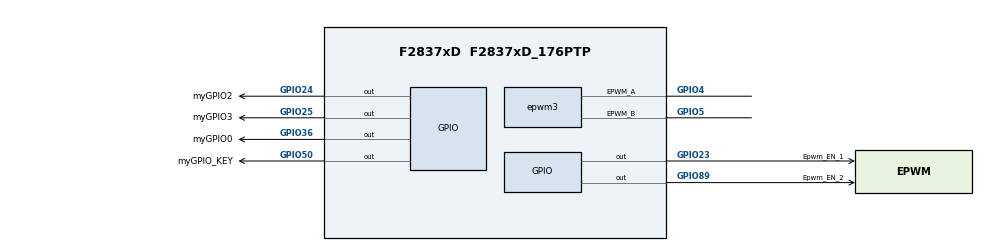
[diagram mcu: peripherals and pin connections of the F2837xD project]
/**
 *
 * @cliArgs --device "F2837xD" --part "F2837xD_176PTP" --package "F2837xD_176PTP" --context "CPU1" --product "C2000WARE@26.01.00.00"
 * @versions {"tool":"1.28.0+4696"}
 */

/**
 * Import the modules used in this configuration.
 */
const adc            = scripting.addModule("/driverlib/adc.js", {}, false);
const adc1           = adc.addInstance();
const adc2           = adc.addInstance();
const adc3           = adc.addInstance();
const cmpss          = scripting.addModule("/driverlib/cmpss.js", {}, false);
const cmpss1         = cmpss.addInstance();
const cmpss2         = cmpss.addInstance();
const cmpss3         = cmpss.addInstance();
const device_support = scripting.addModule("/driverlib/device_support.js");
const epwm           = scripting.addModule("/driverlib/epwm.js", {}, false);
const epwm1          = epwm.addInstance();
const epwm2          = epwm.addInstance();
const epwm3          = epwm.addInstance();
const epwm4          = epwm.addInstance();
const epwm5          = epwm.addInstance();
const epwm6          = epwm.addInstance();
const epwm7          = epwm.addInstance();
const epwm8          = epwm.addInstance();
const epwm9          = epwm.addInstance();
const epwmxbar       = scripting.addModule("/driverlib/epwmxbar.js", {}, false);
const epwmxbar1      = epwmxbar.addInstance();
const gpio           = scripting.addModule("/driverlib/gpio.js", {}, false);
const gpio1          = gpio.addInstance();
const gpio2          = gpio.addInstance();
const gpio3          = gpio.addInstance();
const gpio4          = gpio.addInstance();
const gpio5          = gpio.addInstance();
const gpio6          = gpio.addInstance();
const sysctl         = scripting.addModule("/driverlib/sysctl.js");
const FPUfastRTS     = scripting.addModule("/libraries/math/FPUfastRTS/FPUfastRTS.js", {}, false);
const FPUfastRTS1    = FPUfastRTS.addInstance();

/**
 * Write custom configuration values to the imported modules.
 */
adc1.$name               = "myADC0";
adc1.adcClockPrescaler   = "ADC_CLK_DIV_4_0";
adc1.enabledSOCs         = ["ADC_SOC_NUMBER2","ADC_SOC_NUMBER3","ADC_SOC_NUMBER4","ADC_SOC_NUMBER5"];
adc1.soc2Channel         = "ADC_CH_ADCIN2";
adc1.soc2SampleWindow    = 15;
adc1.soc3Channel         = "ADC_CH_ADCIN3";
adc1.soc3SampleWindow    = 15;
adc1.soc4Channel         = "ADC_CH_ADCIN4";
adc1.soc4SampleWindow    = 15;
adc1.soc5Channel         = "ADC_CH_ADCIN5";
adc1.soc5SampleWindow    = 15;
adc1.useInterrupts       = false;
adc1.interruptPulseMode  = "ADC_PULSE_END_OF_CONV";
adc1.interrupt1SOCSource = "ADC_SOC_NUMBER2";
adc1.soc4Trigger         = "ADC_TRIGGER_EPWM3_SOCA";
adc1.soc2Trigger         = "ADC_TRIGGER_EPWM1_SOCA";
adc1.soc5Trigger         = "ADC_TRIGGER_EPWM1_SOCA";
adc1.soc3Trigger         = "ADC_TRIGGER_EPWM6_SOCA";

adc2.$name             = "myADC1";
adc2.adcBase           = "ADCB_BASE";
adc2.adcClockPrescaler = "ADC_CLK_DIV_4_0";
adc2.enabledSOCs       = ["ADC_SOC_NUMBER0","ADC_SOC_NUMBER1"];
adc2.soc0Channel       = "ADC_CH_ADCIN2";
adc2.soc0SampleWindow  = 15;
adc2.soc1Channel       = "ADC_CH_ADCIN3";
adc2.soc1SampleWindow  = 15;
adc2.soc0Trigger       = "ADC_TRIGGER_EPWM1_SOCA";
adc2.soc1Trigger       = "ADC_TRIGGER_EPWM1_SOCA";

adc3.$name             = "myADC2";
adc3.adcBase           = "ADCC_BASE";
adc3.adcClockPrescaler = "ADC_CLK_DIV_4_0";
adc3.enabledSOCs       = ["ADC_SOC_NUMBER0","ADC_SOC_NUMBER1"];
adc3.soc0SampleWindow  = 15;
adc3.soc0Channel       = "ADC_CH_ADCIN2";
adc3.soc1Channel       = "ADC_CH_ADCIN3";
adc3.soc1SampleWindow  = 15;
adc3.soc1Trigger       = "ADC_TRIGGER_EPWM3_SOCA";
adc3.soc0Trigger       = "ADC_TRIGGER_EPWM6_SOCA";

const multiplier4         = system.clockTree["PLL_IMULT"];
multiplier4.multiplyValue = 20;

const pinFunction3     = system.clockTree["XTAL"];
pinFunction3.XTAL_Freq = 20;

cmpss1.$name                = "myCMPSS1";
cmpss1.enableModule         = true;
cmpss1.hysteresisVal        = "2";
cmpss1.initFilterHigh       = true;
cmpss1.clearFilterLatchHigh = true;
cmpss1.samplePrescaleHigh   = 2;
cmpss1.sampleWindowHigh     = 10;
cmpss1.thresholdHigh        = 7;
cmpss1.lowCompInvert        = true;
cmpss1.samplePrescaleLow    = 2;
cmpss1.sampleWindowLow      = 10;
cmpss1.thresholdLow         = 7;
cmpss1.initFilterLow        = true;
cmpss1.clearFilterLatchLow  = true;
cmpss1.highCTRIPOUT         = "CMPSS_TRIPOUT_FILTER";
cmpss1.highCTRIP            = "CMPSS_TRIP_FILTER";
cmpss1.lowCTRIPOUT          = "CMPSS_TRIPOUT_FILTER";
cmpss1.lowCTRIP             = "CMPSS_TRIP_FILTER";
cmpss1.dacValHigh           = 2916;
cmpss1.dacValLow            = 861;

cmpss2.$name                = "myCMPSS2";
cmpss2.enableModule         = true;
cmpss2.hysteresisVal        = "2";
cmpss2.initFilterHigh       = true;
cmpss2.clearFilterLatchHigh = true;
cmpss2.samplePrescaleHigh   = 2;
cmpss2.sampleWindowHigh     = 10;
cmpss2.thresholdHigh        = 7;
cmpss2.lowCompInvert        = true;
cmpss2.samplePrescaleLow    = 2;
cmpss2.sampleWindowLow      = 10;
cmpss2.thresholdLow         = 7;
cmpss2.initFilterLow        = true;
cmpss2.clearFilterLatchLow  = true;
cmpss2.highCTRIPOUT         = "CMPSS_TRIPOUT_FILTER";
cmpss2.highCTRIP            = "CMPSS_TRIP_FILTER";
cmpss2.lowCTRIPOUT          = "CMPSS_TRIPOUT_FILTER";
cmpss2.lowCTRIP             = "CMPSS_TRIP_FILTER";
cmpss2.cmpssBase            = "CMPSS2_BASE";
cmpss2.dacValLow            = 861;
cmpss2.dacValHigh           = 2916;

cmpss3.enableModule         = true;
cmpss3.hysteresisVal        = "2";
cmpss3.initFilterHigh       = true;
cmpss3.clearFilterLatchHigh = true;
cmpss3.samplePrescaleHigh   = 2;
cmpss3.sampleWindowHigh     = 10;
cmpss3.thresholdHigh        = 7;
cmpss3.lowCompInvert        = true;
cmpss3.samplePrescaleLow    = 2;
cmpss3.sampleWindowLow      = 10;
cmpss3.thresholdLow         = 7;
cmpss3.initFilterLow        = true;
cmpss3.clearFilterLatchLow  = true;
cmpss3.highCTRIPOUT         = "CMPSS_TRIPOUT_FILTER";
cmpss3.highCTRIP            = "CMPSS_TRIP_FILTER";
cmpss3.lowCTRIPOUT          = "CMPSS_TRIPOUT_FILTER";
cmpss3.lowCTRIP             = "CMPSS_TRIP_FILTER";
cmpss3.cmpssBase            = "CMPSS6_BASE";
cmpss3.$name                = "myCMPSS6";
cmpss3.dacValHigh           = 2916;
cmpss3.dacValLow            = 861;

epwm1.epwmTimebase_counterMode                                     = "EPWM_COUNTER_MODE_UP";
epwm1.epwmActionQualifier_EPWM_AQ_OUTPUT_A_shadowMode              = true;
epwm1.epwmActionQualifier_EPWM_AQ_OUTPUT_B_shadowMode              = true;
epwm1.epwmDeadband_enableFED                                       = true;
epwm1.epwmDeadband_polarityFED                                     = "EPWM_DB_POLARITY_ACTIVE_LOW";
epwm1.epwmDeadband_enableRED                                       = true;
epwm1.epwmDeadband_inputFED                                        = "EPWM_DB_INPUT_EPWMB";
epwm1.$name                                                        = "myEPWM1";
epwm1.epwmTimebase_hsClockDiv                                      = "EPWM_HSCLOCK_DIVIDER_1";
epwm1.epwmTimebase_syncOutPulseMode                                = "EPWM_SYNC_OUT_PULSE_ON_COUNTER_ZERO";
epwm1.epwmActionQualifier_EPWM_AQ_OUTPUT_A_ON_TIMEBASE_UP_CMPB     = "EPWM_AQ_OUTPUT_HIGH";
epwm1.epwmEventTrigger_enableInterrupt                             = true;
epwm1.epwmEventTrigger_registerInterrupts                          = true;
epwm1.epwmEventTrigger_interruptSource                             = "EPWM_INT_TBCTR_ZERO";
epwm1.epwmCounterCompare_cmpA                                      = 250;
epwm1.epwmCounterCompare_cmpB                                      = 500;
epwm1.epwmActionQualifier_EPWM_AQ_OUTPUT_B_ON_TIMEBASE_ZERO        = "EPWM_AQ_OUTPUT_LOW";
epwm1.epwmGlobalLoad_gld                                           = true;
epwm1.epwmGlobalLoad_gldPeriod                                     = "1";
epwm1.epwmGlobalLoad_enableOneShot                                 = true;
epwm1.epwmGlobalLoad_oneShotMode                                   = true;
epwm1.epwmCounterCompare_cmpAGld                                   = true;
epwm1.epwmCounterCompare_cmpBGld                                   = true;
epwm1.epwmActionQualifier_continousSwForceReloadModeGld            = true;
epwm1.epwmActionQualifier_EPWM_AQ_OUTPUT_A_gld                     = true;
epwm1.epwmActionQualifier_EPWM_AQ_OUTPUT_B_gld                     = true;
epwm1.epwmActionQualifier_EPWM_AQ_OUTPUT_A_ON_TIMEBASE_ZERO        = "EPWM_AQ_OUTPUT_HIGH";
epwm1.epwmActionQualifier_EPWM_AQ_OUTPUT_A_ON_TIMEBASE_UP_CMPA     = "EPWM_AQ_OUTPUT_LOW";
epwm1.epwmActionQualifier_EPWM_AQ_OUTPUT_B_ON_TIMEBASE_UP_CMPA     = "EPWM_AQ_OUTPUT_LOW";
epwm1.epwmActionQualifier_EPWM_AQ_OUTPUT_B_ON_TIMEBASE_UP_CMPB     = "EPWM_AQ_OUTPUT_HIGH";
epwm1.epwmTimebase_period                                          = 2000;
epwm1.epwmGlobalLoad_gldMode                                       = "EPWM_GL_LOAD_PULSE_CNTR_PERIOD";
epwm1.epwmActionQualifier_continousSwForceReloadMode               = "EPWM_AQ_SW_SH_LOAD_ON_CNTR_PERIOD";
epwm1.epwmEventTrigger_interruptEventCount                         = "2";
epwm1.epwmEventTrigger_EPWM_SOC_A_triggerEnable                    = true;
epwm1.epwmEventTrigger_EPWM_SOC_A_triggerSource                    = "EPWM_SOC_TBCTR_U_CMPC";
epwm1.epwmEventTrigger_EPWM_SOC_A_triggerEventPrescalar            = "1";
epwm1.epwmActionQualifier_EPWM_AQ_OUTPUT_A_continuousSwForceAction = "EPWM_AQ_SW_OUTPUT_LOW";
epwm1.epwmActionQualifier_EPWM_AQ_OUTPUT_B_continuousSwForceAction = "EPWM_AQ_SW_OUTPUT_HIGH";
epwm1.epwmDeadband_delayRED                                        = 60;
epwm1.epwmDeadband_delayFED                                        = 60;
epwm1.epwmDigitalCompare_EPWM_DC_TYPE_DCAH                         = "EPWM_DC_TRIP_TRIPIN4";
epwm1.epwmDigitalCompare_EPWM_TZ_DC_OUTPUT_A1                      = "EPWM_TZ_EVENT_DCXH_HIGH";
epwm1.epwmTripZone_oneShotSource                                   = ["EPWM_TZ_SIGNAL_DCAEVT1"];
epwm1.epwmTripZone_EPWM_TZ_ACTION_EVENT_TZA                        = "EPWM_TZ_ACTION_LOW";
epwm1.epwmTripZone_EPWM_TZ_ACTION_EVENT_TZB                        = "EPWM_TZ_ACTION_LOW";
epwm1.epwmTripZone_tzInterruptSource                               = ["EPWM_TZ_INTERRUPT_OST"];
epwm1.epwmTripZone_registerInterrupts                              = true;
epwm1.epwm.$assign                                                 = "EPWM1";
epwm1.epwmInt.enableInterrupt                                      = true;
epwm1.epwmTZInt.enableInterrupt                                    = true;

epwm2.$name                                                        = "myEPWM2";
epwm2.epwmTimebase_hsClockDiv                                      = "EPWM_HSCLOCK_DIVIDER_1";
epwm2.epwmTimebase_periodLoadEvent                                 = "EPWM_SHADOW_LOAD_MODE_COUNTER_SYNC";
epwm2.epwmTimebase_phaseEnable                                     = true;
epwm2.epwmTimebase_counterMode                                     = "EPWM_COUNTER_MODE_UP";
epwm2.epwmDeadband_inputFED                                        = "EPWM_DB_INPUT_EPWMB";
epwm2.epwmDeadband_polarityFED                                     = "EPWM_DB_POLARITY_ACTIVE_LOW";
epwm2.epwmDeadband_enableRED                                       = true;
epwm2.epwmDeadband_enableFED                                       = true;
epwm2.epwmActionQualifier_EPWM_AQ_OUTPUT_A_ON_TIMEBASE_UP_CMPB     = "EPWM_AQ_OUTPUT_HIGH";
epwm2.epwmCounterCompare_cmpB                                      = 750;
epwm2.epwmCounterCompare_cmpA                                      = 500;
epwm2.epwmTimebase_syncOutPulseMode                                = "EPWM_SYNC_OUT_PULSE_ON_EPWMxSYNCIN";
epwm2.epwmActionQualifier_EPWM_AQ_OUTPUT_B_ON_TIMEBASE_ZERO        = "EPWM_AQ_OUTPUT_LOW";
epwm2.epwmGlobalLoad_gld                                           = true;
epwm2.epwmGlobalLoad_gldPeriod                                     = "1";
epwm2.epwmGlobalLoad_enableOneShot                                 = true;
epwm2.epwmGlobalLoad_oneShotMode                                   = true;
epwm2.epwmGlobalLoad_globalePWMLoadLink                            = "EPWM_LINK_WITH_EPWM_1";
epwm2.epwmActionQualifier_EPWM_AQ_OUTPUT_A_shadowMode              = true;
epwm2.epwmActionQualifier_EPWM_AQ_OUTPUT_B_shadowMode              = true;
epwm2.epwmActionQualifier_EPWM_AQ_OUTPUT_A_gld                     = true;
epwm2.epwmActionQualifier_EPWM_AQ_OUTPUT_B_gld                     = true;
epwm2.epwmActionQualifier_continousSwForceReloadModeGld            = true;
epwm2.epwmCounterCompare_cmpAGld                                   = true;
epwm2.epwmCounterCompare_cmpBGld                                   = true;
epwm2.epwmActionQualifier_EPWM_AQ_OUTPUT_A_ON_TIMEBASE_ZERO        = "EPWM_AQ_OUTPUT_LOW";
epwm2.epwmActionQualifier_EPWM_AQ_OUTPUT_A_ON_TIMEBASE_UP_CMPA     = "EPWM_AQ_OUTPUT_HIGH";
epwm2.epwmActionQualifier_EPWM_AQ_OUTPUT_B_ON_TIMEBASE_UP_CMPA     = "EPWM_AQ_OUTPUT_HIGH";
epwm2.epwmActionQualifier_EPWM_AQ_OUTPUT_B_ON_TIMEBASE_UP_CMPB     = "EPWM_AQ_OUTPUT_LOW";
epwm2.epwmTimebase_period                                          = 2000;
epwm2.epwmGlobalLoad_gldMode                                       = "EPWM_GL_LOAD_PULSE_CNTR_PERIOD";
epwm2.epwmActionQualifier_EPWM_AQ_OUTPUT_A_continuousSwForceAction = "EPWM_AQ_SW_OUTPUT_LOW";
epwm2.epwmActionQualifier_EPWM_AQ_OUTPUT_B_onetimeSwForceAction    = "EPWM_AQ_OUTPUT_HIGH";
epwm2.epwmActionQualifier_EPWM_AQ_OUTPUT_B_continuousSwForceAction = "EPWM_AQ_SW_OUTPUT_HIGH";
epwm2.epwmDeadband_delayRED                                        = 60;
epwm2.epwmDeadband_delayFED                                        = 60;
epwm2.epwmTripZone_EPWM_TZ_ACTION_EVENT_TZA                        = "EPWM_TZ_ACTION_LOW";
epwm2.epwmTripZone_EPWM_TZ_ACTION_EVENT_TZB                        = "EPWM_TZ_ACTION_LOW";
epwm2.epwmTripZone_oneShotSource                                   = ["EPWM_TZ_SIGNAL_DCAEVT1"];
epwm2.epwmDigitalCompare_EPWM_DC_TYPE_DCAH                         = "EPWM_DC_TRIP_TRIPIN4";
epwm2.epwmDigitalCompare_EPWM_TZ_DC_OUTPUT_A1                      = "EPWM_TZ_EVENT_DCXH_HIGH";
epwm2.epwm.$assign                                                 = "EPWM2";

epwm3.$name                                                        = "myEPWM3";
epwm3.epwmTimebase_counterMode                                     = "EPWM_COUNTER_MODE_UP";
epwm3.epwmActionQualifier_EPWM_AQ_OUTPUT_A_shadowMode              = true;
epwm3.epwmActionQualifier_EPWM_AQ_OUTPUT_B_shadowMode              = true;
epwm3.epwmDeadband_enableFED                                       = true;
epwm3.epwmDeadband_polarityFED                                     = "EPWM_DB_POLARITY_ACTIVE_LOW";
epwm3.epwmDeadband_enableRED                                       = true;
epwm3.epwmDeadband_inputFED                                        = "EPWM_DB_INPUT_EPWMB";
epwm3.epwmTimebase_hsClockDiv                                      = "EPWM_HSCLOCK_DIVIDER_1";
epwm3.epwmActionQualifier_EPWM_AQ_OUTPUT_A_ON_TIMEBASE_UP_CMPB     = "EPWM_AQ_OUTPUT_HIGH";
epwm3.epwmCounterCompare_cmpA                                      = 250;
epwm3.epwmCounterCompare_cmpB                                      = 500;
epwm3.epwmActionQualifier_EPWM_AQ_OUTPUT_B_ON_TIMEBASE_ZERO        = "EPWM_AQ_OUTPUT_LOW";
epwm3.epwmGlobalLoad_gld                                           = true;
epwm3.epwmGlobalLoad_gldPeriod                                     = "1";
epwm3.epwmGlobalLoad_enableOneShot                                 = true;
epwm3.epwmGlobalLoad_oneShotMode                                   = true;
epwm3.epwmCounterCompare_cmpAGld                                   = true;
epwm3.epwmCounterCompare_cmpBGld                                   = true;
epwm3.epwmActionQualifier_continousSwForceReloadModeGld            = true;
epwm3.epwmActionQualifier_EPWM_AQ_OUTPUT_A_gld                     = true;
epwm3.epwmActionQualifier_EPWM_AQ_OUTPUT_B_gld                     = true;
epwm3.epwmGlobalLoad_globalePWMLoadLink                            = "EPWM_LINK_WITH_EPWM_1";
epwm3.epwmTimebase_phaseEnable                                     = true;
epwm3.epwmTimebase_syncOutPulseMode                                = "EPWM_SYNC_OUT_PULSE_ON_EPWMxSYNCIN";
epwm3.epwmActionQualifier_EPWM_AQ_OUTPUT_A_ON_TIMEBASE_ZERO        = "EPWM_AQ_OUTPUT_HIGH";
epwm3.epwmActionQualifier_EPWM_AQ_OUTPUT_A_ON_TIMEBASE_UP_CMPA     = "EPWM_AQ_OUTPUT_LOW";
epwm3.epwmActionQualifier_EPWM_AQ_OUTPUT_B_ON_TIMEBASE_UP_CMPA     = "EPWM_AQ_OUTPUT_LOW";
epwm3.epwmActionQualifier_EPWM_AQ_OUTPUT_B_ON_TIMEBASE_UP_CMPB     = "EPWM_AQ_OUTPUT_HIGH";
epwm3.epwmTimebase_period                                          = 2000;
epwm3.epwmTimebase_phaseShift                                      = 667;
epwm3.epwmGlobalLoad_gldMode                                       = "EPWM_GL_LOAD_PULSE_CNTR_PERIOD";
epwm3.epwmEventTrigger_EPWM_SOC_A_triggerEnable                    = true;
epwm3.epwmEventTrigger_EPWM_SOC_A_triggerSource                    = "EPWM_SOC_TBCTR_U_CMPC";
epwm3.epwmEventTrigger_EPWM_SOC_A_triggerEventPrescalar            = "1";
epwm3.epwmActionQualifier_EPWM_AQ_OUTPUT_A_continuousSwForceAction = "EPWM_AQ_SW_OUTPUT_LOW";
epwm3.epwmActionQualifier_EPWM_AQ_OUTPUT_B_continuousSwForceAction = "EPWM_AQ_SW_OUTPUT_HIGH";
epwm3.epwmDeadband_delayRED                                        = 60;
epwm3.epwmDeadband_delayFED                                        = 60;
epwm3.epwmTripZone_EPWM_TZ_ACTION_EVENT_TZA                        = "EPWM_TZ_ACTION_LOW";
epwm3.epwmTripZone_EPWM_TZ_ACTION_EVENT_TZB                        = "EPWM_TZ_ACTION_LOW";
epwm3.epwmTripZone_oneShotSource                                   = ["EPWM_TZ_SIGNAL_DCAEVT1"];
epwm3.epwmDigitalCompare_EPWM_DC_TYPE_DCAH                         = "EPWM_DC_TRIP_TRIPIN4";
epwm3.epwmDigitalCompare_EPWM_TZ_DC_OUTPUT_A1                      = "EPWM_TZ_EVENT_DCXH_HIGH";
epwm3.epwm.epwm_aPin.$assign                                       = "GPIO4";
epwm3.epwm.epwm_bPin.$assign                                       = "GPIO5";

epwm4.$name                                                        = "myEPWM4";
epwm4.epwmTimebase_hsClockDiv                                      = "EPWM_HSCLOCK_DIVIDER_1";
epwm4.epwmTimebase_periodLoadEvent                                 = "EPWM_SHADOW_LOAD_MODE_COUNTER_SYNC";
epwm4.epwmTimebase_phaseEnable                                     = true;
epwm4.epwmTimebase_counterMode                                     = "EPWM_COUNTER_MODE_UP";
epwm4.epwmDeadband_inputFED                                        = "EPWM_DB_INPUT_EPWMB";
epwm4.epwmDeadband_polarityFED                                     = "EPWM_DB_POLARITY_ACTIVE_LOW";
epwm4.epwmDeadband_enableRED                                       = true;
epwm4.epwmDeadband_enableFED                                       = true;
epwm4.epwmActionQualifier_EPWM_AQ_OUTPUT_A_ON_TIMEBASE_UP_CMPB     = "EPWM_AQ_OUTPUT_HIGH";
epwm4.epwmCounterCompare_cmpB                                      = 750;
epwm4.epwmCounterCompare_cmpA                                      = 500;
epwm4.epwmTimebase_syncOutPulseMode                                = "EPWM_SYNC_OUT_PULSE_ON_EPWMxSYNCIN";
epwm4.epwmActionQualifier_EPWM_AQ_OUTPUT_B_ON_TIMEBASE_ZERO        = "EPWM_AQ_OUTPUT_LOW";
epwm4.epwmGlobalLoad_gld                                           = true;
epwm4.epwmGlobalLoad_gldPeriod                                     = "1";
epwm4.epwmGlobalLoad_enableOneShot                                 = true;
epwm4.epwmGlobalLoad_oneShotMode                                   = true;
epwm4.epwmGlobalLoad_globalePWMLoadLink                            = "EPWM_LINK_WITH_EPWM_1";
epwm4.epwmActionQualifier_EPWM_AQ_OUTPUT_A_shadowMode              = true;
epwm4.epwmActionQualifier_EPWM_AQ_OUTPUT_B_shadowMode              = true;
epwm4.epwmActionQualifier_EPWM_AQ_OUTPUT_A_gld                     = true;
epwm4.epwmActionQualifier_EPWM_AQ_OUTPUT_B_gld                     = true;
epwm4.epwmActionQualifier_continousSwForceReloadModeGld            = true;
epwm4.epwmCounterCompare_cmpAGld                                   = true;
epwm4.epwmCounterCompare_cmpBGld                                   = true;
epwm4.epwmActionQualifier_EPWM_AQ_OUTPUT_A_ON_TIMEBASE_ZERO        = "EPWM_AQ_OUTPUT_LOW";
epwm4.epwmActionQualifier_EPWM_AQ_OUTPUT_A_ON_TIMEBASE_UP_CMPA     = "EPWM_AQ_OUTPUT_HIGH";
epwm4.epwmActionQualifier_EPWM_AQ_OUTPUT_B_ON_TIMEBASE_UP_CMPA     = "EPWM_AQ_OUTPUT_HIGH";
epwm4.epwmActionQualifier_EPWM_AQ_OUTPUT_B_ON_TIMEBASE_UP_CMPB     = "EPWM_AQ_OUTPUT_LOW";
epwm4.epwmTimebase_period                                          = 2000;
epwm4.epwmTimebase_phaseShift                                      = 667;
epwm4.epwmGlobalLoad_gldMode                                       = "EPWM_GL_LOAD_PULSE_CNTR_PERIOD";
epwm4.epwmActionQualifier_EPWM_AQ_OUTPUT_A_continuousSwForceAction = "EPWM_AQ_SW_OUTPUT_LOW";
epwm4.epwmActionQualifier_EPWM_AQ_OUTPUT_B_continuousSwForceAction = "EPWM_AQ_SW_OUTPUT_HIGH";
epwm4.epwmDeadband_delayRED                                        = 60;
epwm4.epwmDeadband_delayFED                                        = 60;
epwm4.epwmTripZone_EPWM_TZ_ACTION_EVENT_TZA                        = "EPWM_TZ_ACTION_LOW";
epwm4.epwmTripZone_EPWM_TZ_ACTION_EVENT_TZB                        = "EPWM_TZ_ACTION_LOW";
epwm4.epwmTripZone_oneShotSource                                   = ["EPWM_TZ_SIGNAL_DCAEVT1"];
epwm4.epwmDigitalCompare_EPWM_DC_TYPE_DCAH                         = "EPWM_DC_TRIP_TRIPIN4";
epwm4.epwmDigitalCompare_EPWM_TZ_DC_OUTPUT_A1                      = "EPWM_TZ_EVENT_DCXH_HIGH";
epwm4.epwm.$assign                                                 = "EPWM4";

epwm5.epwmTimebase_counterMode                                     = "EPWM_COUNTER_MODE_UP";
epwm5.epwmActionQualifier_EPWM_AQ_OUTPUT_A_shadowMode              = true;
epwm5.epwmActionQualifier_EPWM_AQ_OUTPUT_B_shadowMode              = true;
epwm5.epwmDeadband_enableFED                                       = true;
epwm5.epwmDeadband_polarityFED                                     = "EPWM_DB_POLARITY_ACTIVE_LOW";
epwm5.epwmDeadband_enableRED                                       = true;
epwm5.epwmDeadband_inputFED                                        = "EPWM_DB_INPUT_EPWMB";
epwm5.$name                                                        = "myEPWM6";
epwm5.epwmTimebase_hsClockDiv                                      = "EPWM_HSCLOCK_DIVIDER_1";
epwm5.epwmTimebase_syncOutPulseMode                                = "EPWM_SYNC_OUT_PULSE_ON_COUNTER_ZERO";
epwm5.epwmActionQualifier_EPWM_AQ_OUTPUT_A_ON_TIMEBASE_UP_CMPB     = "EPWM_AQ_OUTPUT_HIGH";
epwm5.epwmCounterCompare_cmpA                                      = 250;
epwm5.epwmCounterCompare_cmpB                                      = 500;
epwm5.epwmActionQualifier_EPWM_AQ_OUTPUT_B_ON_TIMEBASE_ZERO        = "EPWM_AQ_OUTPUT_LOW";
epwm5.epwmGlobalLoad_gld                                           = true;
epwm5.epwmGlobalLoad_gldPeriod                                     = "1";
epwm5.epwmGlobalLoad_enableOneShot                                 = true;
epwm5.epwmGlobalLoad_oneShotMode                                   = true;
epwm5.epwmCounterCompare_cmpAGld                                   = true;
epwm5.epwmCounterCompare_cmpBGld                                   = true;
epwm5.epwmActionQualifier_continousSwForceReloadModeGld            = true;
epwm5.epwmActionQualifier_EPWM_AQ_OUTPUT_A_gld                     = true;
epwm5.epwmActionQualifier_EPWM_AQ_OUTPUT_B_gld                     = true;
epwm5.epwmGlobalLoad_globalePWMLoadLink                            = "EPWM_LINK_WITH_EPWM_1";
epwm5.epwmTimebase_phaseEnable                                     = true;
epwm5.epwmActionQualifier_EPWM_AQ_OUTPUT_A_ON_TIMEBASE_ZERO        = "EPWM_AQ_OUTPUT_HIGH";
epwm5.epwmActionQualifier_EPWM_AQ_OUTPUT_A_ON_TIMEBASE_UP_CMPA     = "EPWM_AQ_OUTPUT_LOW";
epwm5.epwmActionQualifier_EPWM_AQ_OUTPUT_B_ON_TIMEBASE_UP_CMPA     = "EPWM_AQ_OUTPUT_LOW";
epwm5.epwmActionQualifier_EPWM_AQ_OUTPUT_B_ON_TIMEBASE_UP_CMPB     = "EPWM_AQ_OUTPUT_HIGH";
epwm5.epwmTimebase_period                                          = 2000;
epwm5.epwmTimebase_phaseShift                                      = 1333;
epwm5.epwmGlobalLoad_gldMode                                       = "EPWM_GL_LOAD_PULSE_CNTR_PERIOD";
epwm5.epwmEventTrigger_EPWM_SOC_A_triggerEnable                    = true;
epwm5.epwmEventTrigger_EPWM_SOC_A_triggerSource                    = "EPWM_SOC_TBCTR_U_CMPC";
epwm5.epwmEventTrigger_EPWM_SOC_A_triggerEventPrescalar            = "1";
epwm5.epwmActionQualifier_EPWM_AQ_OUTPUT_A_continuousSwForceAction = "EPWM_AQ_SW_OUTPUT_LOW";
epwm5.epwmActionQualifier_EPWM_AQ_OUTPUT_B_continuousSwForceAction = "EPWM_AQ_SW_OUTPUT_HIGH";
epwm5.epwmDeadband_delayRED                                        = 60;
epwm5.epwmDeadband_delayFED                                        = 60;
epwm5.epwmTripZone_EPWM_TZ_ACTION_EVENT_TZA                        = "EPWM_TZ_ACTION_LOW";
epwm5.epwmTripZone_EPWM_TZ_ACTION_EVENT_TZB                        = "EPWM_TZ_ACTION_LOW";
epwm5.epwmTripZone_oneShotSource                                   = ["EPWM_TZ_SIGNAL_DCAEVT1"];
epwm5.epwmDigitalCompare_EPWM_DC_TYPE_DCAH                         = "EPWM_DC_TRIP_TRIPIN4";
epwm5.epwmDigitalCompare_EPWM_TZ_DC_OUTPUT_A1                      = "EPWM_TZ_EVENT_DCXH_HIGH";
epwm5.epwm.$assign                                                 = "EPWM6";

epwm6.$name                                                        = "myEPWM7";
epwm6.epwmTimebase_hsClockDiv                                      = "EPWM_HSCLOCK_DIVIDER_1";
epwm6.epwmTimebase_periodLoadEvent                                 = "EPWM_SHADOW_LOAD_MODE_COUNTER_SYNC";
epwm6.epwmTimebase_phaseEnable                                     = true;
epwm6.epwmTimebase_counterMode                                     = "EPWM_COUNTER_MODE_UP";
epwm6.epwmDeadband_inputFED                                        = "EPWM_DB_INPUT_EPWMB";
epwm6.epwmDeadband_polarityFED                                     = "EPWM_DB_POLARITY_ACTIVE_LOW";
epwm6.epwmDeadband_enableRED                                       = true;
epwm6.epwmDeadband_enableFED                                       = true;
epwm6.epwmActionQualifier_EPWM_AQ_OUTPUT_A_ON_TIMEBASE_UP_CMPB     = "EPWM_AQ_OUTPUT_HIGH";
epwm6.epwmCounterCompare_cmpB                                      = 750;
epwm6.epwmCounterCompare_cmpA                                      = 500;
epwm6.epwmTimebase_syncOutPulseMode                                = "EPWM_SYNC_OUT_PULSE_ON_EPWMxSYNCIN";
epwm6.epwmActionQualifier_EPWM_AQ_OUTPUT_B_ON_TIMEBASE_ZERO        = "EPWM_AQ_OUTPUT_LOW";
epwm6.epwmGlobalLoad_gld                                           = true;
epwm6.epwmGlobalLoad_gldPeriod                                     = "1";
epwm6.epwmGlobalLoad_enableOneShot                                 = true;
epwm6.epwmGlobalLoad_oneShotMode                                   = true;
epwm6.epwmGlobalLoad_globalePWMLoadLink                            = "EPWM_LINK_WITH_EPWM_1";
epwm6.epwmActionQualifier_EPWM_AQ_OUTPUT_A_shadowMode              = true;
epwm6.epwmActionQualifier_EPWM_AQ_OUTPUT_B_shadowMode              = true;
epwm6.epwmActionQualifier_EPWM_AQ_OUTPUT_A_gld                     = true;
epwm6.epwmActionQualifier_EPWM_AQ_OUTPUT_B_gld                     = true;
epwm6.epwmActionQualifier_continousSwForceReloadModeGld            = true;
epwm6.epwmCounterCompare_cmpAGld                                   = true;
epwm6.epwmCounterCompare_cmpBGld                                   = true;
epwm6.epwmActionQualifier_EPWM_AQ_OUTPUT_A_ON_TIMEBASE_ZERO        = "EPWM_AQ_OUTPUT_LOW";
epwm6.epwmActionQualifier_EPWM_AQ_OUTPUT_A_ON_TIMEBASE_UP_CMPA     = "EPWM_AQ_OUTPUT_HIGH";
epwm6.epwmActionQualifier_EPWM_AQ_OUTPUT_B_ON_TIMEBASE_UP_CMPA     = "EPWM_AQ_OUTPUT_HIGH";
epwm6.epwmActionQualifier_EPWM_AQ_OUTPUT_B_ON_TIMEBASE_UP_CMPB     = "EPWM_AQ_OUTPUT_LOW";
epwm6.epwmTimebase_period                                          = 2000;
epwm6.epwmTimebase_phaseShift                                      = 1333;
epwm6.epwmGlobalLoad_gldMode                                       = "EPWM_GL_LOAD_PULSE_CNTR_PERIOD";
epwm6.epwmActionQualifier_EPWM_AQ_OUTPUT_A_continuousSwForceAction = "EPWM_AQ_SW_OUTPUT_LOW";
epwm6.epwmActionQualifier_EPWM_AQ_OUTPUT_B_continuousSwForceAction = "EPWM_AQ_SW_OUTPUT_HIGH";
epwm6.epwmDeadband_delayRED                                        = 60;
epwm6.epwmDeadband_delayFED                                        = 60;
epwm6.epwmTripZone_EPWM_TZ_ACTION_EVENT_TZA                        = "EPWM_TZ_ACTION_LOW";
epwm6.epwmTripZone_EPWM_TZ_ACTION_EVENT_TZB                        = "EPWM_TZ_ACTION_LOW";
epwm6.epwmTripZone_oneShotSource                                   = ["EPWM_TZ_SIGNAL_DCAEVT1"];
epwm6.epwmDigitalCompare_EPWM_DC_TYPE_DCAH                         = "EPWM_DC_TRIP_TRIPIN4";
epwm6.epwmDigitalCompare_EPWM_TZ_DC_OUTPUT_A1                      = "EPWM_TZ_EVENT_DCXH_HIGH";
epwm6.epwm.$assign                                                 = "EPWM7";

epwm7.$name                                                        = "myEPWM8";
epwm7.epwmTimebase_hsClockDiv                                      = "EPWM_HSCLOCK_DIVIDER_1";
epwm7.epwmTimebase_periodLoadEvent                                 = "EPWM_SHADOW_LOAD_MODE_COUNTER_SYNC";
epwm7.epwmTimebase_phaseEnable                                     = true;
epwm7.epwmTimebase_counterMode                                     = "EPWM_COUNTER_MODE_UP";
epwm7.epwmDeadband_inputFED                                        = "EPWM_DB_INPUT_EPWMB";
epwm7.epwmDeadband_polarityFED                                     = "EPWM_DB_POLARITY_ACTIVE_LOW";
epwm7.epwmDeadband_enableRED                                       = true;
epwm7.epwmDeadband_enableFED                                       = true;
epwm7.epwmCounterCompare_cmpA                                      = 500;
epwm7.epwmTimebase_syncOutPulseMode                                = "EPWM_SYNC_OUT_PULSE_ON_EPWMxSYNCIN";
epwm7.epwmGlobalLoad_gld                                           = true;
epwm7.epwmGlobalLoad_gldPeriod                                     = "1";
epwm7.epwmGlobalLoad_enableOneShot                                 = true;
epwm7.epwmGlobalLoad_oneShotMode                                   = true;
epwm7.epwmGlobalLoad_globalePWMLoadLink                            = "EPWM_LINK_WITH_EPWM_1";
epwm7.epwmActionQualifier_EPWM_AQ_OUTPUT_A_shadowMode              = true;
epwm7.epwmActionQualifier_EPWM_AQ_OUTPUT_B_shadowMode              = true;
epwm7.epwmActionQualifier_EPWM_AQ_OUTPUT_A_gld                     = true;
epwm7.epwmActionQualifier_EPWM_AQ_OUTPUT_B_gld                     = true;
epwm7.epwmActionQualifier_continousSwForceReloadModeGld            = true;
epwm7.epwmCounterCompare_cmpAGld                                   = true;
epwm7.epwmCounterCompare_cmpBGld                                   = true;
epwm7.epwmActionQualifier_EPWM_AQ_OUTPUT_A_ON_TIMEBASE_UP_CMPA     = "EPWM_AQ_OUTPUT_HIGH";
epwm7.epwmActionQualifier_EPWM_AQ_OUTPUT_B_ON_TIMEBASE_UP_CMPA     = "EPWM_AQ_OUTPUT_HIGH";
epwm7.epwmActionQualifier_EPWM_AQ_OUTPUT_B_ON_TIMEBASE_UP_CMPB     = "EPWM_AQ_OUTPUT_LOW";
epwm7.epwmTimebase_period                                          = 2000;
epwm7.epwmGlobalLoad_gldMode                                       = "EPWM_GL_LOAD_PULSE_CNTR_PERIOD";
epwm7.epwmActionQualifier_EPWM_AQ_OUTPUT_A_continuousSwForceAction = "EPWM_AQ_SW_OUTPUT_LOW";
epwm7.epwmActionQualifier_EPWM_AQ_OUTPUT_B_continuousSwForceAction = "EPWM_AQ_SW_OUTPUT_HIGH";
epwm7.epwmCounterCompare_cmpB                                      = 1500;
epwm7.epwmActionQualifier_EPWM_AQ_OUTPUT_A_ON_TIMEBASE_UP_CMPB     = "EPWM_AQ_OUTPUT_LOW";
epwm7.epwmDeadband_delayRED                                        = 60;
epwm7.epwmDeadband_delayFED                                        = 60;
epwm7.epwmTimebase_phaseShift                                      = 1333;
epwm7.epwmTripZone_EPWM_TZ_ACTION_EVENT_TZA                        = "EPWM_TZ_ACTION_LOW";
epwm7.epwmTripZone_EPWM_TZ_ACTION_EVENT_TZB                        = "EPWM_TZ_ACTION_LOW";
epwm7.epwmTripZone_oneShotSource                                   = ["EPWM_TZ_SIGNAL_DCAEVT1"];
epwm7.epwmDigitalCompare_EPWM_DC_TYPE_DCAH                         = "EPWM_DC_TRIP_TRIPIN4";
epwm7.epwmDigitalCompare_EPWM_TZ_DC_OUTPUT_A1                      = "EPWM_TZ_EVENT_DCXH_HIGH";
epwm7.epwm.$assign                                                 = "EPWM8";

epwm8.$name                                                        = "myEPWM9";
epwm8.epwmTimebase_hsClockDiv                                      = "EPWM_HSCLOCK_DIVIDER_1";
epwm8.epwmTimebase_periodLoadEvent                                 = "EPWM_SHADOW_LOAD_MODE_COUNTER_SYNC";
epwm8.epwmTimebase_phaseEnable                                     = true;
epwm8.epwmTimebase_counterMode                                     = "EPWM_COUNTER_MODE_UP";
epwm8.epwmDeadband_inputFED                                        = "EPWM_DB_INPUT_EPWMB";
epwm8.epwmDeadband_polarityFED                                     = "EPWM_DB_POLARITY_ACTIVE_LOW";
epwm8.epwmDeadband_enableRED                                       = true;
epwm8.epwmDeadband_enableFED                                       = true;
epwm8.epwmCounterCompare_cmpA                                      = 500;
epwm8.epwmTimebase_syncOutPulseMode                                = "EPWM_SYNC_OUT_PULSE_ON_EPWMxSYNCIN";
epwm8.epwmGlobalLoad_gld                                           = true;
epwm8.epwmGlobalLoad_gldPeriod                                     = "1";
epwm8.epwmGlobalLoad_enableOneShot                                 = true;
epwm8.epwmGlobalLoad_oneShotMode                                   = true;
epwm8.epwmGlobalLoad_globalePWMLoadLink                            = "EPWM_LINK_WITH_EPWM_1";
epwm8.epwmActionQualifier_EPWM_AQ_OUTPUT_A_shadowMode              = true;
epwm8.epwmActionQualifier_EPWM_AQ_OUTPUT_B_shadowMode              = true;
epwm8.epwmActionQualifier_EPWM_AQ_OUTPUT_A_gld                     = true;
epwm8.epwmActionQualifier_EPWM_AQ_OUTPUT_B_gld                     = true;
epwm8.epwmActionQualifier_continousSwForceReloadModeGld            = true;
epwm8.epwmCounterCompare_cmpAGld                                   = true;
epwm8.epwmCounterCompare_cmpBGld                                   = true;
epwm8.epwmActionQualifier_EPWM_AQ_OUTPUT_A_ON_TIMEBASE_UP_CMPA     = "EPWM_AQ_OUTPUT_HIGH";
epwm8.epwmActionQualifier_EPWM_AQ_OUTPUT_B_ON_TIMEBASE_UP_CMPA     = "EPWM_AQ_OUTPUT_HIGH";
epwm8.epwmActionQualifier_EPWM_AQ_OUTPUT_B_ON_TIMEBASE_UP_CMPB     = "EPWM_AQ_OUTPUT_LOW";
epwm8.epwmTimebase_period                                          = 2000;
epwm8.epwmGlobalLoad_gldMode                                       = "EPWM_GL_LOAD_PULSE_CNTR_PERIOD";
epwm8.epwmActionQualifier_EPWM_AQ_OUTPUT_A_continuousSwForceAction = "EPWM_AQ_SW_OUTPUT_LOW";
epwm8.epwmActionQualifier_EPWM_AQ_OUTPUT_B_continuousSwForceAction = "EPWM_AQ_SW_OUTPUT_HIGH";
epwm8.epwmCounterCompare_cmpB                                      = 1500;
epwm8.epwmActionQualifier_EPWM_AQ_OUTPUT_A_ON_TIMEBASE_UP_CMPB     = "EPWM_AQ_OUTPUT_LOW";
epwm8.epwmTimebase_phaseShift                                      = 667;
epwm8.epwmDeadband_delayRED                                        = 60;
epwm8.epwmDeadband_delayFED                                        = 60;
epwm8.epwmTripZone_EPWM_TZ_ACTION_EVENT_TZA                        = "EPWM_TZ_ACTION_LOW";
epwm8.epwmTripZone_EPWM_TZ_ACTION_EVENT_TZB                        = "EPWM_TZ_ACTION_LOW";
epwm8.epwmTripZone_oneShotSource                                   = ["EPWM_TZ_SIGNAL_DCAEVT1"];
epwm8.epwmDigitalCompare_EPWM_DC_TYPE_DCAH                         = "EPWM_DC_TRIP_TRIPIN4";
epwm8.epwmDigitalCompare_EPWM_TZ_DC_OUTPUT_A1                      = "EPWM_TZ_EVENT_DCXH_HIGH";
epwm8.epwm.$assign                                                 = "EPWM9";

epwm9.$name                                                        = "myEPWM10";
epwm9.epwmTimebase_hsClockDiv                                      = "EPWM_HSCLOCK_DIVIDER_1";
epwm9.epwmTimebase_periodLoadEvent                                 = "EPWM_SHADOW_LOAD_MODE_COUNTER_SYNC";
epwm9.epwmTimebase_phaseEnable                                     = true;
epwm9.epwmTimebase_counterMode                                     = "EPWM_COUNTER_MODE_UP";
epwm9.epwmDeadband_inputFED                                        = "EPWM_DB_INPUT_EPWMB";
epwm9.epwmDeadband_polarityFED                                     = "EPWM_DB_POLARITY_ACTIVE_LOW";
epwm9.epwmDeadband_enableRED                                       = true;
epwm9.epwmDeadband_enableFED                                       = true;
epwm9.epwmCounterCompare_cmpA                                      = 500;
epwm9.epwmTimebase_syncOutPulseMode                                = "EPWM_SYNC_OUT_PULSE_ON_EPWMxSYNCIN";
epwm9.epwmGlobalLoad_gld                                           = true;
epwm9.epwmGlobalLoad_gldPeriod                                     = "1";
epwm9.epwmGlobalLoad_enableOneShot                                 = true;
epwm9.epwmGlobalLoad_oneShotMode                                   = true;
epwm9.epwmGlobalLoad_globalePWMLoadLink                            = "EPWM_LINK_WITH_EPWM_1";
epwm9.epwmActionQualifier_EPWM_AQ_OUTPUT_A_shadowMode              = true;
epwm9.epwmActionQualifier_EPWM_AQ_OUTPUT_B_shadowMode              = true;
epwm9.epwmActionQualifier_EPWM_AQ_OUTPUT_A_gld                     = true;
epwm9.epwmActionQualifier_EPWM_AQ_OUTPUT_B_gld                     = true;
epwm9.epwmActionQualifier_continousSwForceReloadModeGld            = true;
epwm9.epwmCounterCompare_cmpAGld                                   = true;
epwm9.epwmCounterCompare_cmpBGld                                   = true;
epwm9.epwmActionQualifier_EPWM_AQ_OUTPUT_A_ON_TIMEBASE_UP_CMPA     = "EPWM_AQ_OUTPUT_HIGH";
epwm9.epwmActionQualifier_EPWM_AQ_OUTPUT_B_ON_TIMEBASE_UP_CMPA     = "EPWM_AQ_OUTPUT_HIGH";
epwm9.epwmActionQualifier_EPWM_AQ_OUTPUT_B_ON_TIMEBASE_UP_CMPB     = "EPWM_AQ_OUTPUT_LOW";
epwm9.epwmTimebase_period                                          = 2000;
epwm9.epwmGlobalLoad_gldMode                                       = "EPWM_GL_LOAD_PULSE_CNTR_PERIOD";
epwm9.epwmActionQualifier_EPWM_AQ_OUTPUT_A_continuousSwForceAction = "EPWM_AQ_SW_OUTPUT_LOW";
epwm9.epwmActionQualifier_EPWM_AQ_OUTPUT_B_continuousSwForceAction = "EPWM_AQ_SW_OUTPUT_HIGH";
epwm9.epwmCounterCompare_cmpB                                      = 1500;
epwm9.epwmActionQualifier_EPWM_AQ_OUTPUT_A_ON_TIMEBASE_UP_CMPB     = "EPWM_AQ_OUTPUT_LOW";
epwm9.epwmDeadband_delayRED                                        = 60;
epwm9.epwmDeadband_delayFED                                        = 60;
epwm9.epwmTripZone_EPWM_TZ_ACTION_EVENT_TZA                        = "EPWM_TZ_ACTION_LOW";
epwm9.epwmTripZone_EPWM_TZ_ACTION_EVENT_TZB                        = "EPWM_TZ_ACTION_LOW";
epwm9.epwmTripZone_oneShotSource                                   = ["EPWM_TZ_SIGNAL_DCAEVT1"];
epwm9.epwmDigitalCompare_EPWM_DC_TYPE_DCAH                         = "EPWM_DC_TRIP_TRIPIN4";
epwm9.epwmDigitalCompare_EPWM_TZ_DC_OUTPUT_A1                      = "EPWM_TZ_EVENT_DCXH_HIGH";
epwm9.epwm.$assign                                                 = "EPWM10";

epwmxbar1.$name           = "myEPWMXBAR4";
epwmxbar1.mux1Config      = "XBAR_EPWM_MUX01_INPUTXBAR1";
epwmxbar1.mux3Config      = "XBAR_EPWM_MUX03_INPUTXBAR2";
epwmxbar1.mux4Config      = "XBAR_EPWM_MUX04_ECAP3_OUT";
epwmxbar1.mux5Config      = "XBAR_EPWM_MUX05_INPUTXBAR3";
epwmxbar1.mux6Config      = "XBAR_EPWM_MUX06_ECAP4_OUT";
epwmxbar1.mux7Config      = "XBAR_EPWM_MUX07_INPUTXBAR4";
epwmxbar1.mux8Config      = "XBAR_EPWM_MUX08_ECAP5_OUT";
epwmxbar1.mux9Config      = "XBAR_EPWM_MUX09_INPUTXBAR5";
epwmxbar1.mux11Config     = "XBAR_EPWM_MUX11_INPUTXBAR6";
epwmxbar1.mux12Config     = "XBAR_EPWM_MUX12_CMPSS7_CTRIPH_OR_L";
epwmxbar1.mux14Config     = "XBAR_EPWM_MUX14_EXTSYNCOUT";
epwmxbar1.mux16Config     = "XBAR_EPWM_MUX16_SD1FLT1_COMPH_OR_COMPL";
epwmxbar1.mux18Config     = "XBAR_EPWM_MUX18_SD1FLT2_COMPH_OR_COMPL";
epwmxbar1.mux20Config     = "XBAR_EPWM_MUX20_SD1FLT3_COMPH_OR_COMPL";
epwmxbar1.mux22Config     = "XBAR_EPWM_MUX22_SD1FLT4_COMPH_OR_COMPL";
epwmxbar1.mux24Config     = "XBAR_EPWM_MUX24_SD2FLT1_COMPH_OR_COMPL";
epwmxbar1.mux26Config     = "XBAR_EPWM_MUX26_SD2FLT2_COMPH_OR_COMPL";
epwmxbar1.mux28Config     = "XBAR_EPWM_MUX28_SD2FLT3_COMPH_OR_COMPL";
epwmxbar1.mux30Config     = "XBAR_EPWM_MUX30_SD2FLT4_COMPH_OR_COMPL";
epwmxbar1.mux2Config      = "XBAR_EPWM_MUX02_CMPSS2_CTRIPH_OR_L";
epwmxbar1.mux10Config     = "XBAR_EPWM_MUX10_CMPSS6_CTRIPH_OR_L";
epwmxbar1.sourceSignals   = ["CMPSS1_CTRIPH_OR_L","CMPSS2_CTRIPH_OR_L","CMPSS6_CTRIPH_OR_L"];
epwmxbar1.useSourceSelect = true;

gpio1.$name           = "myGPIO0";
gpio1.direction       = "GPIO_DIR_MODE_OUT";
gpio1.gpioPin.$assign = "GPIO36";

gpio2.direction       = "GPIO_DIR_MODE_OUT";
gpio2.$name           = "Epwm_EN_1";
gpio2.gpioPin.$assign = "GPIO23";

gpio3.$name           = "myGPIO2";
gpio3.direction       = "GPIO_DIR_MODE_OUT";
gpio3.gpioPin.$assign = "GPIO24";

gpio4.$name           = "myGPIO3";
gpio4.direction       = "GPIO_DIR_MODE_OUT";
gpio4.gpioPin.$assign = "GPIO25";

gpio5.direction       = "GPIO_DIR_MODE_OUT";
gpio5.$name           = "Epwm_EN_2";
gpio5.gpioPin.$assign = "GPIO89";

gpio6.$name           = "myGPIO_KEY";
gpio6.padConfig       = "PULLUP";
gpio6.gpioPin.$assign = "GPIO50";

sysctl.splitCode = true;

FPUfastRTS1.$name = "myFFR0";

/**
 * Pinmux solution for unlocked pins/peripherals. This ensures that minor changes to the automatic solver in a future
 * version of the tool will not impact the pinmux you originally saw.  These lines can be completely deleted in order to
 * re-solve from scratch.
 */
epwm1.epwm.epwm_aPin.$suggestSolution = "GPIO0";
epwm1.epwm.epwm_bPin.$suggestSolution = "GPIO1";
epwm2.epwm.epwm_aPin.$suggestSolution = "GPIO2";
epwm2.epwm.epwm_bPin.$suggestSolution = "GPIO3";
epwm3.epwm.$suggestSolution           = "EPWM3";
epwm4.epwm.epwm_aPin.$suggestSolution = "GPIO6";
epwm4.epwm.epwm_bPin.$suggestSolution = "GPIO7";
epwm5.epwm.epwm_aPin.$suggestSolution = "GPIO10";
epwm5.epwm.epwm_bPin.$suggestSolution = "GPIO11";
epwm6.epwm.epwm_aPin.$suggestSolution = "GPIO12";
epwm6.epwm.epwm_bPin.$suggestSolution = "GPIO13";
epwm7.epwm.epwm_aPin.$suggestSolution = "GPIO14";
epwm7.epwm.epwm_bPin.$suggestSolution = "GPIO15";
epwm8.epwm.epwm_aPin.$suggestSolution = "GPIO16";
epwm8.epwm.epwm_bPin.$suggestSolution = "GPIO17";
epwm9.epwm.epwm_aPin.$suggestSolution = "GPIO18";
epwm9.epwm.epwm_bPin.$suggestSolution = "GPIO19";
